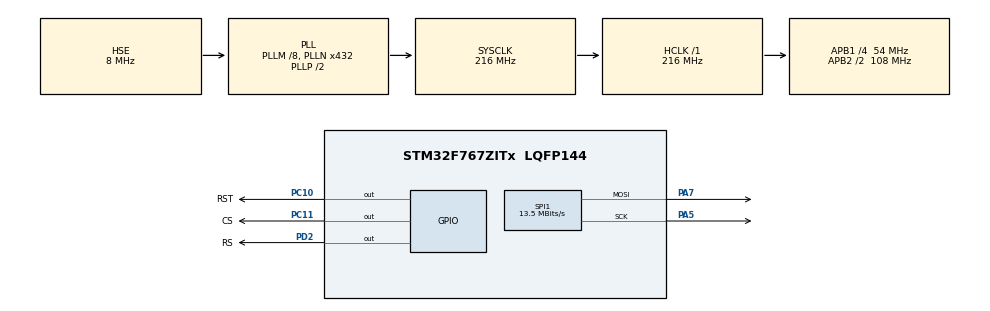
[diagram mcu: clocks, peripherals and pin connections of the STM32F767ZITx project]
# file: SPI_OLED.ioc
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CORTEX_M7.ART_ACCLERATOR_ENABLE=1
CORTEX_M7.CPU_DCache=Enabled
CORTEX_M7.CPU_ICache=Enabled
CORTEX_M7.PREFETCH_ENABLE=1
Mcu.Family=STM32F7
Mcu.Name=STM32F767ZITx
Mcu.Package=LQFP144
NVIC.PriorityGroup=NVIC_PRIORITYGROUP_4
PA5.Mode=TX_Only_Simplex_Unidirect_Master
PA5.Signal=SPI1_SCK
PA7.Mode=TX_Only_Simplex_Unidirect_Master
PA7.Signal=SPI1_MOSI
PC10.GPIO_Label=RST
PC10.Signal=GPIO_Output
PC11.GPIO_Label=CS
PC11.Signal=GPIO_Output
PC14/OSC32_IN.Mode=LSE-External-Oscillator
PC14/OSC32_IN.Signal=RCC_OSC32_IN
PC15/OSC32_OUT.Mode=LSE-External-Oscillator
PC15/OSC32_OUT.Signal=RCC_OSC32_OUT
PD2.GPIO_Label=RS
PD2.Signal=GPIO_Output
PH0/OSC_IN.Mode=HSE-External-Clock-Source
PH0/OSC_IN.Signal=RCC_OSC_IN
PH1/OSC_OUT.Mode=HSE-External-Clock-Source
PH1/OSC_OUT.Signal=RCC_OSC_OUT
ProjectManager.HeapSize=0x200
ProjectManager.StackSize=0x400
ProjectManager.TargetToolchain=MDK-ARM V5
RCC.AHBFreq_Value=216000000
RCC.APB1CLKDivider=RCC_HCLK_DIV4
RCC.APB1Freq_Value=54000000
RCC.APB1TimFreq_Value=108000000
RCC.APB2CLKDivider=RCC_HCLK_DIV2
RCC.APB2Freq_Value=108000000
RCC.APB2TimFreq_Value=216000000
RCC.CortexFreq_Value=216000000
RCC.HCLKFreq_Value=216000000
RCC.HSE_VALUE=8000000
RCC.HSI_VALUE=16000000
RCC.PLLM=8
RCC.PLLN=432
RCC.PLLSourceVirtual=RCC_PLLSOURCE_HSE
RCC.SYSCLKFreq_VALUE=216000000
RCC.SYSCLKSource=RCC_SYSCLKSOURCE_PLLCLK
RCC.USBFreq_Value=216000000
RCC.VCOOutputFreq_Value=432000000
SPI1.BaudRatePrescaler=SPI_BAUDRATEPRESCALER_8
SPI1.CalculateBaudRate=13.5 MBits/s
SPI1.DataSize=SPI_DATASIZE_8BIT
SPI1.Direction=SPI_DIRECTION_2LINES
SPI1.Mode=SPI_MODE_MASTER
SPI1.VirtualType=VM_MASTER
board=custom

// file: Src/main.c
/* USER CODE BEGIN Header */
/**
  ******************************************************************************
  * @file           : main.c
  * @brief          : Main program body
  ******************************************************************************
  * @attention
  *
  * <h2><center>&copy; Copyright (c) 2019 STMicroelectronics.
  * All rights reserved.</center></h2>
  *
  * This software component is licensed by ST under BSD 3-Clause license,
  * the "License"; You may not use this file except in compliance with the
  * License. You may obtain a copy of the License at:
  *                        opensource.org/licenses/BSD-3-Clause
  *
  ******************************************************************************
  */
/* USER CODE END Header */

#include "main.h"
#include "spi.h"
#include "gpio.h"

/* USER CODE BEGIN Includes */
#include "oled.h"
/* USER CODE END Includes */

void SystemClock_Config(void);

int main(void)
{

  /* Enable I-Cache---------------------------------------------------------*/
  SCB_EnableICache();

  /* Enable D-Cache---------------------------------------------------------*/
  SCB_EnableDCache();

  /* MCU Configuration--------------------------------------------------------*/

  /* Reset of all peripherals, Initializes the Flash interface and the Systick. */
  HAL_Init();

  /* Configure the system clock */
  SystemClock_Config();

  /* Initialize all configured peripherals */
  MX_GPIO_Init();
  MX_SPI1_Init();
  /* USER CODE BEGIN 2 */
	OLED_Init();
  /* USER CODE END 2 */

  /* Infinite loop */
  while (1)
  {

    /* USER CODE BEGIN 3 */
		OLED_CLS();
		OLED_Display_String(0,3,"HELLO",1);
		HAL_Delay(1000);
		OLED_Display_Chinese(0,0,0);
		OLED_Display_Chinese(18,0,1);
		OLED_Display_Chinese(36,0,2);
		OLED_Display_Chinese(54,0,3);
		HAL_Delay(1000);

  }
  /* USER CODE END 3 */
}

void SystemClock_Config(void)
{
  RCC_OscInitTypeDef RCC_OscInitStruct = {0};
  RCC_ClkInitTypeDef RCC_ClkInitStruct = {0};

  /** Configure LSE Drive Capability
  */
  HAL_PWR_EnableBkUpAccess();
  /** Configure the main internal regulator output voltage
  */
  __HAL_RCC_PWR_CLK_ENABLE();
  __HAL_PWR_VOLTAGESCALING_CONFIG(PWR_REGULATOR_VOLTAGE_SCALE1);
  /** Initializes the CPU, AHB and APB busses clocks
  */
  RCC_OscInitStruct.OscillatorType = RCC_OSCILLATORTYPE_HSE;
  RCC_OscInitStruct.HSEState = RCC_HSE_BYPASS;
  RCC_OscInitStruct.PLL.PLLState = RCC_PLL_ON;
  RCC_OscInitStruct.PLL.PLLSource = RCC_PLLSOURCE_HSE;
  RCC_OscInitStruct.PLL.PLLM = 8;
  RCC_OscInitStruct.PLL.PLLN = 432;
  RCC_OscInitStruct.PLL.PLLP = RCC_PLLP_DIV2;
  RCC_OscInitStruct.PLL.PLLQ = 2;
  if (HAL_RCC_OscConfig(&RCC_OscInitStruct) != HAL_OK)
  {
    Error_Handler();
  }
  /** Activate the Over-Drive mode
  */
  if (HAL_PWREx_EnableOverDrive() != HAL_OK)
  {
    Error_Handler();
  }
  /** Initializes the CPU, AHB and APB busses clocks
  */
  RCC_ClkInitStruct.ClockType = RCC_CLOCKTYPE_HCLK|RCC_CLOCKTYPE_SYSCLK
                              |RCC_CLOCKTYPE_PCLK1|RCC_CLOCKTYPE_PCLK2;
  RCC_ClkInitStruct.SYSCLKSource = RCC_SYSCLKSOURCE_PLLCLK;
  RCC_ClkInitStruct.AHBCLKDivider = RCC_SYSCLK_DIV1;
  RCC_ClkInitStruct.APB1CLKDivider = RCC_HCLK_DIV4;
  RCC_ClkInitStruct.APB2CLKDivider = RCC_HCLK_DIV2;

  if (HAL_RCC_ClockConfig(&RCC_ClkInitStruct, FLASH_LATENCY_7) != HAL_OK)
  {
    Error_Handler();
  }
}

void Error_Handler(void)
{
}

/************************ (C) COPYRIGHT STMicroelectronics *****END OF FILE****/
